# LPC176x5x register map
File version: 0.2
CPU: CM3 r0p0, little endian, no MPU, no FPU, 0x5 interrupt priority bits, 0x0 interrupts
Registers are 32-bit, read-write, no defined reset value unless marked. A register's access mark holds for its fields unless they carry their own. Offsets are from the block's base; [hi:lo] are bit positions; 'fields as' and 'values as' point back to an identical list.

## PINCONNECT — Pin connect block
Base 0x4002C000
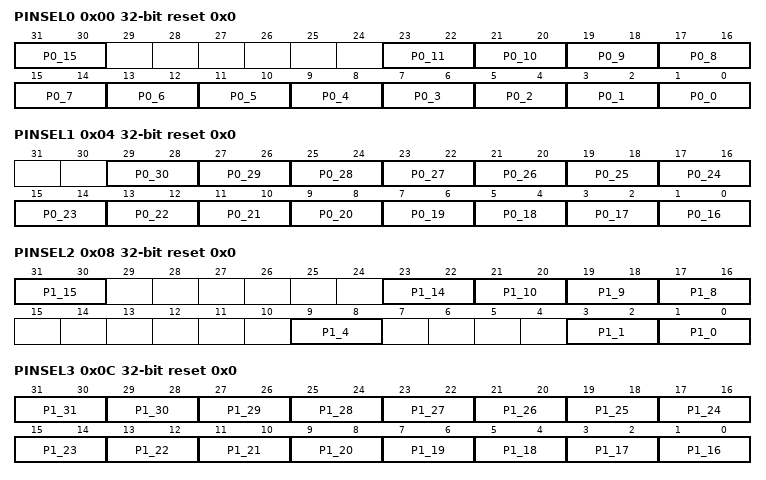
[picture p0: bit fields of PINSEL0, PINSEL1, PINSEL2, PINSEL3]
0x00 PINSEL0 reset 0x0 — Pin function select register 0.
  [31:30] P0_15 — Pin function select P0.15.
    0=GPIO_P0 (GPIO P0.15); 1=TXD1; 2=SCK0; 3=SCK
  [23:22] P0_11 — Pin function select P0.11.
    0=GPIO_P0 (GPIO P0.11); 1=RXD2; 2=SCL2; 3=MAT3 (MAT3.1)
  [21:20] P0_10 — Pin function select P0.10.
    0=GPIO_P0 (GPIO P0.10); 1=TXD2; 2=SDA2; 3=MAT3 (MAT3.0)
  [19:18] P0_9 — Pin function select P0.9.
    0=GPIO_P0 (GPIO P0.9); 1=I2STX_SDA; 2=MOSI1; 3=MAT2 (MAT2.3)
  [17:16] P0_8 — Pin function select P0.8.
    0=GPIO_P0 (GPIO P0.8.); 1=I2STX_WS; 2=MISO1; 3=MAT2 (MAT2.2)
  [15:14] P0_7 — Pin function select P0.7.
    0=GPIO_P0 (GPIO P0.7.); 1=I2STX_CLK; 2=SCK1; 3=MAT2 (MAT2.1)
  [13:12] P0_6 — Pin function select P0.6.
    0=GPIO_P0 (GPIO P0.6.); 1=I2SRX_SDA; 2=SSEL1; 3=MAT2 (MAT2.0)
  [11:10] P0_5 — Pin function select P0.5.
    0=GPIO_P0 (GPIO P0.5.); 1=I2SRX_WS; 2=TD2; 3=CAP2 (CAP2.1)
  [9:8] P0_4 — Pin function select P0.4.
    0=GPIO_P0 (GPIO P0.4.); 1=I2SRX_CLK; 2=RD2; 3=CAP2 (CAP2.0)
  [7:6] P0_3 — Pin function select P0.3.
    0=GPIO_P0 (GPIO P0.3.); 1=RXD0; 2=AD0 (AD0.6)
  [5:4] P0_2 — Pin function select P0.2.
    0=GPIO_P0 (GPIO P0.2); 1=TXD0; 2=AD0 (AD0.7)
  [3:2] P0_1 — Pin function select P0.1.
    0=GPIO_P0 (GPIO P0.1); 1=TD1; 2=RXD3; 3=SCL1
  [1:0] P0_0 — Pin function select P0.0.
    0=GPIO_P0 (GPIO P0.0); 1=RD1; 2=TXD3; 3=SDA1
0x04 PINSEL1 reset 0x0 — Pin function select register 1.
  [29:28] P0_30 — Pin function select P0.30.
    0=GPIO_P0 (GPIO P0.30); 1=USB_DM
  [27:26] P0_29 — Pin function select P0.29
    0=GPIO_P0 (GPIO P0.29); 1=USB_DP
  [25:24] P0_28 — Pin function select P0.28.
    0=GPIO_P0 (GPIO P0.28); 1=SCL0; 2=USB_SCL
  [23:22] P0_27 — Pin function select P0.27.
    0=GPIO_P0 (GPIO P0.27); 1=SDA0; 2=USB_SDA
  [21:20] P0_26 — Pin function select P0.26.
    0=GPIO_P0 (GPIO P0.26); 1=AD0 (AD0.3); 2=AOUT; 3=RXD3
  [19:18] P0_25 — Pin function select P0.25.
    0=GPIO_P0 (GPIO P0.25); 1=AD0 (AD0.2); 2=I2SRX_SDA; 3=TXD3
  [17:16] P0_24 — Pin function select P0.24.
    0=GPIO_P0 (GPIO P0.24.); 1=AD0 (AD0.1); 2=I2SRX_WS; 3=CAP3 (CAP3.1)
  [15:14] P0_23 — Pin function select P023.
    0=GPIO_P0 (GPIO P0.23.); 1=AD0 (AD0.0); 2=I2SRX_CLK; 3=CAP3 (CAP3.0)
  [13:12] P0_22 — Pin function select P022
    0=GPIO_P0 (GPIO P0.22.); 1=RTS1; 3=TD1
  [11:10] P0_21 — Pin function select P0.21.
    0=GPIO_PORT_0 (GPIO Port 0.21.); 1=RI1; 3=RD1
  [9:8] P0_20 — Pin function select P0.20.
    0=GPIO_P0 (GPIO P0.20.); 1=DTR1; 3=SCL1
  [7:6] P0_19 — Pin function select P019.
    0=GPIO_P0 (GPIO P0.19.); 1=DSR1; 3=SDA1
  [5:4] P0_18 — Pin function select P0.18.
    0=GPIO_P0 (GPIO P0.18); 1=DCD1; 2=MOSI0; 3=MOSI
  [3:2] P0_17 — Pin function select P0.17.
    0=GPIO_P0 (GPIO P0.17); 1=CTS1; 2=MISO0; 3=MISO
  [1:0] P0_16 — Pin function select P0.16.
    0=GPIO_P0 (GPIO P0.16); 1=RXD1; 2=SSEL0; 3=SSEL
0x08 PINSEL2 reset 0x0 — Pin function select register 2.
  [31:30] P1_15 — Pin function select P1.15.
    0=GPIO_P1 (GPIO P1.15); 1=ENET_REF_CLK
  [23:22] P1_14 — Pin function select P1.14.
    0=GPIO_P1 (GPIO P1.14); 1=ENET_RX_ER
  [21:20] P1_10 — Pin function select P1.10.
    0=GPIO_P1 (GPIO P1.10); 1=ENET_RXD1
  [19:18] P1_9 — Pin function select P1.9.
    0=GPIO_PORT_1 (GPIO Port 1.9); 1=ENET_RXD0
  [17:16] P1_8 — Pin function select P1.8.
    0=GPIO_P1 (GPIO P1.8.); 1=ENET_CRS
  [9:8] P1_4 — Pin function select P1.4.
    0=GPIO_P1 (GPIO P1.4.); 1=ENET_TX_EN
  [3:2] P1_1 — Pin function select P1.1.
    0=GPIO_P1 (GPIO P1.1); 1=ENET_TXD1
  [1:0] P1_0 — Pin function select P1.0.
    0=GPIO_P1 (GPIO P1.0); 1=ENET_TXD0
0x0C PINSEL3 reset 0x0 — Pin function select register 3.
  [31:30] P1_31 — Pin function select P1.31.
    0=GPIO_PORT_1 (GPIO Port 1.31); 2=SCK1; 3=AD0 (AD0.5)
  [29:28] P1_30 — Pin function select P1.30.
    0=GPIO_P1 (GPIO P1.30); 2=VBUS; 3=AD0 (AD0.4)
  [27:26] P1_29 — Pin function select P1.29
    0=GPIO_P1 (GPIO P1.29); 1=MCOB2; 2=PCAP1 (PCAP1.1); 3=MAT0 (MAT0.1)
  [25:24] P1_28 — Pin function select P1.28.
    0=GPIO_P1 (GPIO P1.28); 1=MCOA2; 2=PCAP1 (PCAP1.0); 3=MAT0 (MAT0.0)
  [23:22] P1_27 — Pin function select P1.27.
    0=GPIO_P1 (GPIO P1.27); 1=CLKOUT; 2=USB_OVRCR; 3=CAP0 (CAP0.1)
  [21:20] P1_26 — Pin function select P1.26.
    0=GPIO_P1 (GPIO P1.26); 1=MCOB1; 2=PWM1 (PWM1.6); 3=CAP0 (CAP0.0)
  [19:18] P1_25 — Pin function select P1.25.
    0=GPIO_P1 (GPIO P1.25); 1=MCOA1; 3=MAT1 (MAT1.1)
  [17:16] P1_24 — Pin function select P1.24.
    0=GPIO_P1 (GPIO P1.24.); 1=MCI2; 2=PWM1 (PWM1.5); 3=MOSI0
  [15:14] P1_23 — Pin function select P1.23.
    0=GPIO_P1 (GPIO P1.23.); 1=MCI1; 2=PWM1 (PWM1.4); 3=MISO0
  [13:12] P1_22 — Pin function select P1.22
    0=GPIO_P1 (GPIO P1.22.); 1=MCOB0; 2=USB_PWRD; 3=MAT1 (MAT1.0)
  [11:10] P1_21 — Pin function select P1.21.
    0=GPIO_P1 (GPIO P1.21.); 1=MCABORT; 2=PWM1 (PWM1.3); 3=SSEL0
  [9:8] P1_20 — Pin function select P1.20.
    0=GPIO_P1 (GPIO P1.20.); 1=MCI0; 2=PWM1 (PWM1.2); 3=SCK0
  [7:6] P1_19 — Pin function select P1.19.
    0=GPIO_P1 (GPIO P1.19.); 1=MCOA0; 2=USB_PPWR; 3=CAP1 (CAP1.1)
  [5:4] P1_18 — Pin function select P1.18.
    0=GPIO_P1 (GPIO P1.18); 1=USB_UP_LED; 2=PWM1 (PWM1.1); 3=CAP1 (CAP1.0)
  [3:2] P1_17 — Pin function select P1.17.
    0=GPIO_P1 (GPIO P1.17); 1=ENET_MDIO
  [1:0] P1_16 — Pin function select P1.16.
    0=GPIO_P1 (GPIO P1.16); 1=ENET_MDC
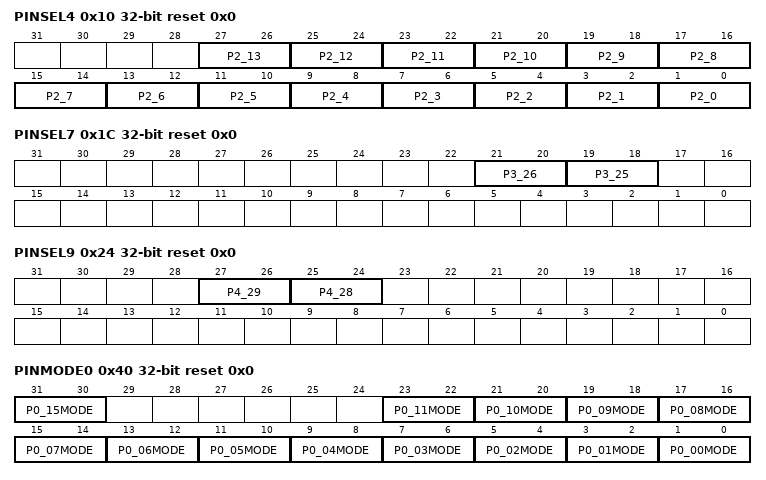
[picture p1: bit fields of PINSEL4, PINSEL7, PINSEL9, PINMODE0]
0x10 PINSEL4 reset 0x0 — Pin function select register 4
  [27:26] P2_13 — Pin function select P2.13.
    0=GPIO_P2 (GPIO P2.13); 1=EINT3; 3=I2STX_SDA
  [25:24] P2_12 — Pin function select P2.12.
    0=GPIO_P2 (GPIO P2.12); 1=EINT2; 3=I2STX_WS
  [23:22] P2_11 — Pin function select P2.11.
    0=GPIO_P2 (GPIO P2.11); 1=EINT1; 3=I2STX_CLK
  [21:20] P2_10 — Pin function select P2.10.
    0=GPIO_P2 (GPIO P2.10); 1=EINT0; 2=NMI
  [19:18] P2_9 — Pin function select P2.9.
    0=GPIO_P2 (GPIO P2.9); 1=USB_CONNECT; 2=RXD2; 3=ENET_MDIO
  [17:16] P2_8 — Pin function select P2.8.
    0=GPIO_P2 (GPIO P2.8.); 1=TD2; 2=TXD2; 3=ENET_MDC
  [15:14] P2_7 — Pin function select P2.7.
    0=GPIO_P2 (GPIO P2.7.); 1=RD2; 2=RTS1
  [13:12] P2_6 — Pin function select P2.6.
    0=GPIO_P2 (GPIO P2.6.); 1=PCAP1 (PCAP1.0); 2=RI1
  [11:10] P2_5 — Pin function select P2.5.
    0=GPIO_P2 (GPIO P2.5.); 1=PWM1 (PWM1.6); 2=DTR1
  [9:8] P2_4 — Pin function select P2.4.
    0=GPIO_P2 (GPIO P2.4.); 1=PWM1 (PWM1.5); 2=DSR1
  [7:6] P2_3 — Pin function select P2.3.
    0=GPIO_P2 (GPIO P2.3.); 1=PWM1 (PWM1.4); 2=DCD1
  [5:4] P2_2 — Pin function select P2.2.
    0=GPIO_P2 (GPIO P2.2); 1=PWM1 (PWM1.3); 2=CTS1
  [3:2] P2_1 — Pin function select P2.1.
    0=GPIO_P2 (GPIO P2.1); 1=PWM1 (PWM1.2); 2=RXD1
  [1:0] P2_0 — Pin function select P2.0.
    0=GPIO_P2 (GPIO P2.0); 1=PWM1 (PWM1.1); 2=TXD1
0x1C PINSEL7 reset 0x0 — Pin function select register 7
  [21:20] P3_26 — Pin function select P3.26.
    0=GPIO_P3 (GPIO P3.26); 1=STCLK; 2=MAT0 (MAT0.1); 3=PWM1 (PWM1.3)
  [19:18] P3_25 — Pin function select P3.25.
    0=GPIO_P3 (GPIO P3.25); 2=MAT0 (MAT0.0); 3=PWM1 (PWM1.2)
0x24 PINSEL9 reset 0x0 — Pin function select register 9
  [27:26] P4_29 — Pin function select P4.29.
    0=GPIO_P4 (GPIO P4.29); 1=TX_MCLK; 2=MAT2 (MAT2.1); 3=RXD3
  [25:24] P4_28 — Pin function select P4.28.
    0=GPIO_P4 (GPIO P4.28); 1=RX_MCLK; 2=MAT2 (MAT2.0); 3=TXD3
0x28 PINSEL10 reset 0x0 — Pin function select register 10
  [3] TPIUCTRL — TPIU interface pins control.
    0=DISABLED (Disabled. TPIU interface is disabled.); 1=ENABLED (Enabled. TPIU interface is enabled. TPIU signals are available on the pins hosting them regardless of the PINSEL4 content.)
0x40 PINMODE0 reset 0x0 — Pin mode select register 0
  [31:30] P0_15MODE — Port 0 pin 15 control.
    0=PULL_UP (Pull-up. P0.15 pin has a pull-up resistor enabled.); 1=REPEATER (Repeater. P0.15 pin has repeater mode enabled.); 2=DISABLED (Disabled. P0.15 pin has neither pull-up nor pull-down.); 3=PULL_DOWN (Pull-down. P0.15 has a pull-down resistor enabled.)
  [23:22] P0_11MODE — Port 0 pin 11 control.
    0=PULL_UP (Pull-up. P0.11 pin has a pull-up resistor enabled.); 1=REPEATER (Repeater. P0.11 pin has repeater mode enabled.); 2=DISABLED (Disabled. P0.11 pin has neither pull-up nor pull-down.); 3=PULL_DOWN (Pull-down. P0.11 has a pull-down resistor enabled.)
  [21:20] P0_10MODE — Port 0 pin 10 control.
    0=PULL_UP (Pull-up. P0.10 pin has a pull-up resistor enabled.); 1=REPEATER (Repeater. P0.10 pin has repeater mode enabled.); 2=DISABLED (Disabled. P0.10 pin has neither pull-up nor pull-down.); 3=PULL_DOWN (Pull-down. P0.10 has a pull-down resistor enabled.)
  [19:18] P0_09MODE — Port 0 pin 9 control.
    0=PULL_UP (Pull-up. P0.9 pin has a pull-up resistor enabled.); 1=REPEATER (Repeater. P0.9 pin has repeater mode enabled.); 2=DISABLED (Disabled. P0.9 pin has neither pull-up nor pull-down.); 3=PULL_DOWN (Pull-down. P0.9 has a pull-down resistor enabled.)
  [17:16] P0_08MODE — Port 0 pin 8 control.
    0=PULL_UP (Pull-up. P0.8 pin has a pull-up resistor enabled.); 1=REPEATER (Repeater. P0.8 pin has repeater mode enabled.); 2=DISABLED (Disabled. P0.8 pin has neither pull-up nor pull-down.); 3=PULL_DOWN (Pull-down. P0.8 has a pull-down resistor enabled.)
  [15:14] P0_07MODE — Port 0 pin 7 control.
    0=PULL_UP (Pull-up. P0.7 pin has a pull-up resistor enabled.); 1=REPEATER (Repeater. P0.7 pin has repeater mode enabled.); 2=DISABLED (Disabled. P0.7 pin has neither pull-up nor pull-down.); 3=PULL_DOWN (Pull-down. P0.7 has a pull-down resistor enabled.)
  [13:12] P0_06MODE — Port 0 pin 6 control.
    0=PULL_UP (Pull-up. P0.6 pin has a pull-up resistor enabled.); 1=DISABLED (Disabled. Repeater. P0.6 pin has repeater mode enabled.); 2=DISABLED (Disabled. P0.6 pin has neither pull-up nor pull-down.); 3=PULL_DOWN (Pull-down. P0.6 has a pull-down resistor enabled.)
  [11:10] P0_05MODE — Port 0 pin 5 control.
    0=PULL_UP (Pull-up. P0.5 pin has a pull-up resistor enabled.); 1=REPEATER (Repeater. P0.5 pin has repeater mode enabled.); 2=DISABLED (Disabled. P0.5 pin has neither pull-up nor pull-down.); 3=PULL_DOWN (Pull-down. P0.5 has a pull-down resistor enabled.)
  [9:8] P0_04MODE — Port 0 pin 4 control.
    0=PULL_UP (Pull-up. P0.4 pin has a pull-up resistor enabled.); 1=REPEATER (Repeater. P0.4 pin has repeater mode enabled.); 2=DISABLED (Disabled. P0.4 pin has neither pull-up nor pull-down.); 3=PULL_DOWN (Pull-down. P0.4 has a pull-down resistor enabled.)
  [7:6] P0_03MODE — Port 0 pin 3 control.
    0=PULL_UP (Pull-up. P0.3 pin has a pull-up resistor enabled.); 1=REPEATER (Repeater. P0.3 pin has repeater mode enabled.); 2=DISABLED (Disabled. P0.3 pin has neither pull-up nor pull-down.); 3=PULL_DOWN (Pull-down. P0.3 has a pull-down resistor enabled.)
  [5:4] P0_02MODE — Port 0 pin 2 control.
    0=PULL_UP (Pull-up. P0.2 pin has a pull-up resistor enabled.); 1=REPEATER (Repeater. P0.2 pin has repeater mode enabled.); 2=DISABLED (Disabled. P0.2 pin has neither pull-up nor pull-down.); 3=PULL_DOWN (Pull-down. P0.2 has a pull-down resistor enabled.)
  [3:2] P0_01MODE — Port 0 pin 1 control.
    0=PULL_UP (Pull-up. P0.1 pin has a pull-up resistor enabled.); 1=REPEATER (Repeater. P0.1 pin has repeater mode enabled.); 2=DISABLED (Disabled. P0.1 pin has neither pull-up nor pull-down.); 3=PULL_DOWN (Pull-down. P0.1 has a pull-down resistor enabled.)
  [1:0] P0_00MODE — Port 0 pin 0 on-chip pull-up/down resistor control.
    0=PULL_UP (Pull-up. P0.0 pin has a pull-up resistor enabled.); 1=REPEATER (Repeater. P0.0 pin has repeater mode enabled.); 2=DISABLED (Disabled. P0.0 pin has neither pull-up nor pull-down.); 3=PULL_DOWN (Pull-down. P0.0 has a pull-down resistor enabled.)
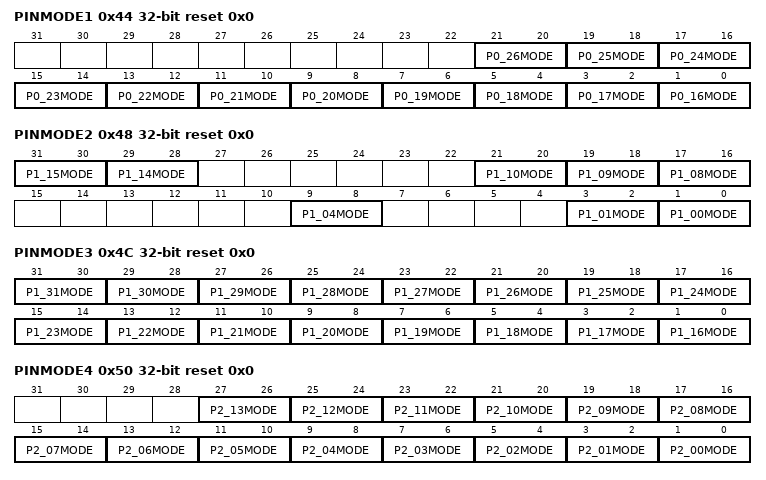
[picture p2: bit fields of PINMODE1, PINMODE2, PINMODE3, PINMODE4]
0x44 PINMODE1 reset 0x0 — Pin mode select register 1
  [21:20] P0_26MODE — Port 1 pin 26 control.
    0=PULL_UP (Pull-up. P0.26 pin has a pull-up resistor enabled.); 1=REPEATER (Repeater. P0.26 pin has repeater mode enabled.); 2=DISABLED (Disabled. P0.26 pin has neither pull-up nor pull-down.); 3=PULL_DOWN (Pull-down. P0.26 has a pull-down resistor enabled.)
  [19:18] P0_25MODE — Port 1 pin 25 control.
    0=PULL_UP (Pull-up. P0.25 pin has a pull-up resistor enabled.); 1=REPEATER (Repeater. P0.25 pin has repeater mode enabled.); 2=DISABLED (Disabled. P0.25 pin has neither pull-up nor pull-down.); 3=PULL_DOWN (Pull-down. P0.25 has a pull-down resistor enabled.)
  [17:16] P0_24MODE — Port 1 pin 24 control.
    0=PULL_UP (Pull-up. P0.24 pin has a pull-up resistor enabled.); 1=REPEATER (Repeater. P0.24 pin has repeater mode enabled.); 2=DISABLED (Disabled. P0.24 pin has neither pull-up nor pull-down.); 3=PULL_DOWN (Pull-down. P0.24 has a pull-down resistor enabled.)
  [15:14] P0_23MODE — Port 1 pin 23 control.
    0=PULL_UP (Pull-up. P0.23 pin has a pull-up resistor enabled.); 1=REPEATER (Repeater. P0.23 pin has repeater mode enabled.); 2=DISABLED (Disabled. P0.23 pin has neither pull-up nor pull-down.); 3=PULL_DOWN (Pull-down. P0.23 has a pull-down resistor enabled.)
  [13:12] P0_22MODE — Port 1 pin 22 control.
    0=PULL_UP (Pull-up. P0.22 pin has a pull-up resistor enabled.); 1=REPEATER (Repeater. P0.22 pin has repeater mode enabled.); 2=DISABLED (Disabled. P0.22 pin has neither pull-up nor pull-down.); 3=PULL_DOWN (Pull-down. P0.22 has a pull-down resistor enabled.)
  [11:10] P0_21MODE — Port 1 pin 21 control.
    0=PULL_UP (Pull-up. P0.21 pin has a pull-up resistor enabled.); 1=REPEATER (Repeater. P0.21 pin has repeater mode enabled.); 2=DISABLED (Disabled. P0.21 pin has neither pull-up nor pull-down.); 3=PULL_DOWN (Pull-down. P0.21 has a pull-down resistor enabled.)
  [9:8] P0_20MODE — Port 1 pin 20 control.
    0=PULL_UP (Pull-up. P0.20 pin has a pull-up resistor enabled.); 1=REPEATER (Repeater. P0.20 pin has repeater mode enabled.); 2=DISABLED (Disabled. P0.20 pin has neither pull-up nor pull-down.); 3=PULL_DOWN (Pull-down. P0.20 has a pull-down resistor enabled.)
  [7:6] P0_19MODE — Port 1 pin 19 control.
    0=PULL_UP (Pull-up. P0.19 pin has a pull-up resistor enabled.); 1=REPEATER (Repeater. P0.19 pin has repeater mode enabled.); 2=DISABLED (Disabled. P0.19 pin has neither pull-up nor pull-down.); 3=PULL_DOWN (Pull-down. P0.19 has a pull-down resistor enabled.)
  [5:4] P0_18MODE — Port 1 pin 18 control.
    0=PULL_UP (Pull-up. P0.18 pin has a pull-up resistor enabled.); 1=REPEATER (Repeater. P0.18 pin has repeater mode enabled.); 2=DISABLED (Disabled. P0.18 pin has neither pull-up nor pull-down.); 3=PULL_DOWN (Pull-down. P0.18 has a pull-down resistor enabled.)
  [3:2] P0_17MODE — Port 1 pin 17 control.
    0=PULL_UP (Pull-up. P0.17 pin has a pull-up resistor enabled.); 1=REPEATER (Repeater. P0.17 pin has repeater mode enabled.); 2=DISABLED (Disabled. P0.17 pin has neither pull-up nor pull-down.); 3=PULL_DOWN (Pull-down. P0.17 has a pull-down resistor enabled.)
  [1:0] P0_16MODE — Port 1 pin 16 control.
    0=PULL_UP (Pull-up. P0.16 pin has a pull-up resistor enabled.); 1=REPEATER (Repeater. P0.16 pin has repeater mode enabled.); 2=DISABLED (Disabled. P0.16 pin has neither pull-up nor pull-down.); 3=PULL_DOWN (Pull-down. P0.16 has a pull-down resistor enabled.)
0x48 PINMODE2 reset 0x0 — Pin mode select register 2
  [31:30] P1_15MODE — Port 1 pin 15 control.
    0=PULL_UP (Pull-up. P1.15 pin has a pull-up resistor enabled.); 1=REPEATER (Repeater. P1.15 pin has repeater mode enabled.); 2=DISABLED (Disabled. P1.15 pin has neither pull-up nor pull-down.); 3=PULL_DOWN (Pull-down. P1.15 has a pull-down resistor enabled.)
  [29:28] P1_14MODE — Port 1 pin 14 control.
    0=PULL_UP (Pull-up. P1.14 pin has a pull-up resistor enabled.); 1=REPEATER (Repeater. P1.14 pin has repeater mode enabled.); 2=DISABLED (Disabled. P1.14 pin has neither pull-up nor pull-down.); 3=PULL_DOWN (Pull-down. P1.14 has a pull-down resistor enabled.)
  [21:20] P1_10MODE — Port 1 pin 10 control.
    0=PULL_UP (Pull-up. P1.10 pin has a pull-up resistor enabled.); 1=REPEATER (Repeater. P1.10 pin has repeater mode enabled.); 2=DISABLED (Disabled. P1.10 pin has neither pull-up nor pull-down.); 3=PULL_DOWN (Pull-down. P1.10 has a pull-down resistor enabled.)
  [19:18] P1_09MODE — Port 1 pin 9 control.
    0=PULL_UP (Pull-up. P1.9 pin has a pull-up resistor enabled.); 1=REPEATER (Repeater. P1.9 pin has repeater mode enabled.); 2=DISABLED (Disabled. P1.9 pin has neither pull-up nor pull-down.); 3=PULL_DOWN (Pull-down. P1.9 has a pull-down resistor enabled.)
  [17:16] P1_08MODE — Port 1 pin 8 control.
    0=PULL_UP (Pull-up. P1.8 pin has a pull-up resistor enabled.); 1=REPEATER (Repeater. P1.8 pin has repeater mode enabled.); 2=DISABLED (Disabled. P1.8 pin has neither pull-up nor pull-down.); 3=PULL_DOWN (Pull-down. P1.8 has a pull-down resistor enabled.)
  [9:8] P1_04MODE — Port 1 pin 4 control.
    0=PULL_UP (Pull-up. P1.4 pin has a pull-up resistor enabled.); 1=REPEATER (Repeater. P1.4 pin has repeater mode enabled.); 2=DISABLED (Disabled. P1.4 pin has neither pull-up nor pull-down.); 3=PULL_DOWN (Pull-down. P1.4 has a pull-down resistor enabled.)
  [3:2] P1_01MODE — Port 1 pin 1 control.
    0=PULL_UP (Pull-up. P1.1 pin has a pull-up resistor enabled.); 1=REPEATER (Repeater. P1.1 pin has repeater mode enabled.); 2=DISABLED (Disabled. P1.1 pin has neither pull-up nor pull-down.); 3=PULL_DOWN (Pull-down. P1.1 has a pull-down resistor enabled.)
  [1:0] P1_00MODE — Port 1 pin 0 control.
    0=PULL_UP (Pull-up. P1.0 pin has a pull-up resistor enabled.); 1=REPEATER (Repeater. P1.0 pin has repeater mode enabled.); 2=DISABLED (Disabled. P1.0 pin has neither pull-up nor pull-down.); 3=PULL_DOWN (Pull-down. P1.0 has a pull-down resistor enabled.)
0x4C PINMODE3 reset 0x0 — Pin mode select register 3.
  [31:30] P1_31MODE — Port 1 pin 31 control.
    0=PULL_UP (Pull-up. P1.31 pin has a pull-up resistor enabled.); 1=REPEATER (Repeater. P1.31 pin has repeater mode enabled.); 2=DISABLED (Disabled. P1.31 pin has neither pull-up nor pull-down.); 3=PULL_DOWN (Pull-down. P1.31 has a pull-down resistor enabled.)
  [29:28] P1_30MODE — Port 1 pin 30 control.
    0=PULL_UP (Pull-up. P1.30 pin has a pull-up resistor enabled.); 1=REPEATER (Repeater. P1.30 pin has repeater mode enabled.); 2=DISABLED (Disabled. P1.30 pin has neither pull-up nor pull-down.); 3=PULL_DOWN (Pull-down. P1.30 has a pull-down resistor enabled.)
  [27:26] P1_29MODE — Port 1 pin 29 control.
    0=PULL_UP (Pull-up. P1.29 pin has a pull-up resistor enabled.); 1=REPEATER (Repeater. P1.29 pin has repeater mode enabled.); 2=DISABLED (Disabled. P1.29 pin has neither pull-up nor pull-down.); 3=PULL_DOWN (Pull-down. P1.29 has a pull-down resistor enabled.)
  [25:24] P1_28MODE — Port 1 pin 28 control.
    0=PULL_UP (Pull-up. P1.28 pin has a pull-up resistor enabled.); 1=REPEATER (Repeater. P1.28 pin has repeater mode enabled.); 2=DISABLED (Disabled. P1.28 pin has neither pull-up nor pull-down.); 3=PULL_DOWN (Pull-down. P1.28 has a pull-down resistor enabled.)
  [23:22] P1_27MODE — Port 1 pin 27 control.
    0=PULL_UP (Pull-up. P1.27 pin has a pull-up resistor enabled.); 1=REPEATER (Repeater. P1.27 pin has repeater mode enabled.); 2=DISABLED (Disabled. P1.27 pin has neither pull-up nor pull-down.); 3=PULL_DOWN (Pull-down. P1.27 has a pull-down resistor enabled.)
  [21:20] P1_26MODE — Port 1 pin 26 control.
    0=PULL_UP (Pull-up. P1.26 pin has a pull-up resistor enabled.); 1=REPEATER (Repeater. P1.26 pin has repeater mode enabled.); 2=DISABLED (Disabled. P1.26 pin has neither pull-up nor pull-down.); 3=PULL_DOWN (Pull-down. P1.26 has a pull-down resistor enabled.)
  [19:18] P1_25MODE — Port 1 pin 25 control.
    0=PULL_UP (Pull-up. P1.25 pin has a pull-up resistor enabled.); 1=REPEATER (Repeater. P1.25 pin has repeater mode enabled.); 2=DISABLED (Disabled. P1.25 pin has neither pull-up nor pull-down.); 3=PULL_DOWN (Pull-down. P1.25 has a pull-down resistor enabled.)
  [17:16] P1_24MODE — Port 1 pin 24 control.
    0=PULL_UP (Pull-up. P1.24 pin has a pull-up resistor enabled.); 1=REPEATER (Repeater. P1.24 pin has repeater mode enabled.); 2=DISABLED (Disabled. P1.24 pin has neither pull-up nor pull-down.); 3=PULL_DOWN (Pull-down. P1.24 has a pull-down resistor enabled.)
  [15:14] P1_23MODE — Port 1 pin 23 control.
    0=PULL_UP (Pull-up. P1.23 pin has a pull-up resistor enabled.); 1=REPEATER (Repeater. P1.23 pin has repeater mode enabled.); 2=DISABLED (Disabled. P1.23 pin has neither pull-up nor pull-down.); 3=PULL_DOWN (Pull-down. P1.23 has a pull-down resistor enabled.)
  [13:12] P1_22MODE — Port 1 pin 22 control.
    0=PULL_UP (Pull-up. P1.22 pin has a pull-up resistor enabled.); 1=REPEATER (Repeater. P1.22 pin has repeater mode enabled.); 2=DISABLED (Disabled. P1.22 pin has neither pull-up nor pull-down.); 3=PULL_DOWN (Pull-down. P1.22 has a pull-down resistor enabled.)
  [11:10] P1_21MODE — Port 1 pin 21 control.
    0=PULL_UP (Pull-up. P1.21 pin has a pull-up resistor enabled.); 1=REPEATER (Repeater. P1.21 pin has repeater mode enabled.); 2=DISABLED (Disabled. P1.21 pin has neither pull-up nor pull-down.); 3=PULL_DOWN (Pull-down. P1.21 has a pull-down resistor enabled.)
  [9:8] P1_20MODE — Port 1 pin 20 control.
    0=PULL_UP (Pull-up. P1.20 pin has a pull-up resistor enabled.); 1=REPEATER (Repeater. P1.20 pin has repeater mode enabled.); 2=DISABLED (Disabled. P1.20 pin has neither pull-up nor pull-down.); 3=PULL_DOWN (Pull-down. P1.20 has a pull-down resistor enabled.)
  [7:6] P1_19MODE — Port 1 pin 19 control.
    0=PULL_UP (Pull-up. P1.19 pin has a pull-up resistor enabled.); 1=REPEATER (Repeater. P1.19 pin has repeater mode enabled.); 2=DISABLED (Disabled. P1.19 pin has neither pull-up nor pull-down.); 3=PULL_DOWN (Pull-down. P1.19 has a pull-down resistor enabled.)
  [5:4] P1_18MODE — Port 1 pin 18 control.
    0=PULL_UP (Pull-up. P1.18 pin has a pull-up resistor enabled.); 1=REPEATER (Repeater. P1.18 pin has repeater mode enabled.); 2=DISABLED (Disabled. P1.18 pin has neither pull-up nor pull-down.); 3=PULL_DOWN (Pull-down. P1.18 has a pull-down resistor enabled.)
  [3:2] P1_17MODE — Port 1 pin 17 control.
    0=PULL_UP (Pull-up. P1.17 pin has a pull-up resistor enabled.); 1=REPEATER (Repeater. P1.17 pin has repeater mode enabled.); 2=DISABLED (Disabled. P1.17 pin has neither pull-up nor pull-down.); 3=PULL_DOWN (Pull-down. P1.17 has a pull-down resistor enabled.)
  [1:0] P1_16MODE — Port 1 pin 16 control.
    0=PULL_UP (Pull-up. P1.16 pin has a pull-up resistor enabled.); 1=REPEATER (Repeater. P1.16 pin has repeater mode enabled.); 2=DISABLED (Disabled. P1.16 pin has neither pull-up nor pull-down.); 3=PULL_DOWN (Pull-down. P1.16 has a pull-down resistor enabled.)
0x50 PINMODE4 reset 0x0 — Pin mode select register 4
  [27:26] P2_13MODE — Port 2 pin 13 control.
    0=PULL_UP (Pull-up. P2.13 pin has a pull-up resistor enabled.); 1=REPEATER (Repeater. P2.13 pin has repeater mode enabled.); 2=DISABLED (Disabled. P2.13 pin has neither pull-up nor pull-down.); 3=PULL_DOWN (Pull-down. P2.13 has a pull-down resistor enabled.)
  [25:24] P2_12MODE — Port 2 pin 12 control.
    0=PULL_UP (Pull-up. P2.12 pin has a pull-up resistor enabled.); 1=REPEATER (Repeater. P2.12 pin has repeater mode enabled.); 2=DISABLED (Disabled. P2.12 pin has neither pull-up nor pull-down.); 3=PULL_DOWN (Pull-down. P2.12 has a pull-down resistor enabled.)
  [23:22] P2_11MODE — Port 2 pin 11 control.
    0=PULL_UP (Pull-up. P2.11 pin has a pull-up resistor enabled.); 1=REPEATER (Repeater. P2.11 pin has repeater mode enabled.); 2=DISABLED (Disabled. P2.11 pin has neither pull-up nor pull-down.); 3=PULL_DOWN (Pull-down. P2.11 has a pull-down resistor enabled.)
  [21:20] P2_10MODE — Port 2 pin 10 control.
    0=PULL_UP (Pull-up. P2.10 pin has a pull-up resistor enabled.); 1=REPEATER (Repeater. P2.10 pin has repeater mode enabled.); 2=DISABLED (Disabled. P2.10 pin has neither pull-up nor pull-down.); 3=PULL_DOWN (Pull-down. P2.10 has a pull-down resistor enabled.)
  [19:18] P2_09MODE — Port 2 pin 9 control.
    0=PULL_UP (Pull-up. P2.9 pin has a pull-up resistor enabled.); 1=REPEATER (Repeater. P2.9 pin has repeater mode enabled.); 2=DISABLED (Disabled. P2.9 pin has neither pull-up nor pull-down.); 3=PULL_DOWN (Pull-down. P2.9 has a pull-down resistor enabled.)
  [17:16] P2_08MODE — Port 2 pin 8 control.
    0=PULL_UP (Pull-up. P2.8 pin has a pull-up resistor enabled.); 1=REPEATER (Repeater. P2.8 pin has repeater mode enabled.); 2=DISABLED (Disabled. P2.8 pin has neither pull-up nor pull-down.); 3=PULL_DOWN (Pull-down. P2.8 has a pull-down resistor enabled.)
  [15:14] P2_07MODE — Port 2 pin 7 control.
    0=PULL_UP (Pull-up. P2.7 pin has a pull-up resistor enabled.); 1=REPEATER (Repeater. P2.7 pin has repeater mode enabled.); 2=DISABLED (Disabled. P2.7 pin has neither pull-up nor pull-down.); 3=PULL_DOWN (Pull-down. P2.7 has a pull-down resistor enabled.)
  [13:12] P2_06MODE — Port 2 pin 6 control.
    0=PULL_UP (Pull-up. P2.6 pin has a pull-up resistor enabled.); 1=REPEATER (Repeater. P2.6 pin has repeater mode enabled.); 2=DISABLED (Disabled. P2.6 pin has neither pull-up nor pull-down.); 3=PULL_DOWN (Pull-down. P2.6 has a pull-down resistor enabled.)
  [11:10] P2_05MODE — Port 2 pin 5 control.
    0=PULL_UP (Pull-up. P2.5 pin has a pull-up resistor enabled.); 1=REPEATER (Repeater. P2.5 pin has repeater mode enabled.); 2=DISABLED (Disabled. P2.5 pin has neither pull-up nor pull-down.); 3=PULL_DOWN (Pull-down. P2.5 has a pull-down resistor enabled.)
  [9:8] P2_04MODE — Port 2 pin 4 control.
    0=PULL_UP (Pull-up. P2.4 pin has a pull-up resistor enabled.); 1=REPEATER (Repeater. P2.4 pin has repeater mode enabled.); 2=DISABLED (Disabled. P2.4 pin has neither pull-up nor pull-down.); 3=PULL_DOWN (Pull-down. P2.4 has a pull-down resistor enabled.)
  [7:6] P2_03MODE — Port 2 pin 3 control.
    0=PULL_UP (Pull-up. P2.3 pin has a pull-up resistor enabled.); 1=REPEATER (Repeater. P2.3 pin has repeater mode enabled.); 2=DISABLED (Disabled. P2.3 pin has neither pull-up nor pull-down.); 3=PULL_DOWN (Pull-down. P2.3 has a pull-down resistor enabled.)
  [5:4] P2_02MODE — Port 2 pin 2 control.
    0=PULL_UP (Pull-up. P2.2 pin has a pull-up resistor enabled.); 1=REPEATER (Repeater. P2.2 pin has repeater mode enabled.); 2=DISABLED (Disabled. P2.2 pin has neither pull-up nor pull-down.); 3=PULL_DOWN (Pull-down. P2.2 has a pull-down resistor enabled.)
  [3:2] P2_01MODE — Port 2 pin 1 control.
    0=PULL_UP (Pull-up. P2.1 pin has a pull-up resistor enabled.); 1=REPEATER (Repeater. P2.1 pin has repeater mode enabled.); 2=DISABLED (Disabled. P2.1 pin has neither pull-up nor pull-down.); 3=PULL_DOWN (Pull-down. P2.1 has a pull-down resistor enabled.)
  [1:0] P2_00MODE — Port 2 pin 0 control.
    0=PULL_UP (Pull-up. P2.0 pin has a pull-up resistor enabled.); 1=REPEATER (Repeater. P2.0 pin has repeater mode enabled.); 2=DISABLED (Disabled. P2.0 pin has neither pull-up nor pull-down.); 3=PULL_DOWN (Pull-down. P2.0 has a pull-down resistor enabled.)
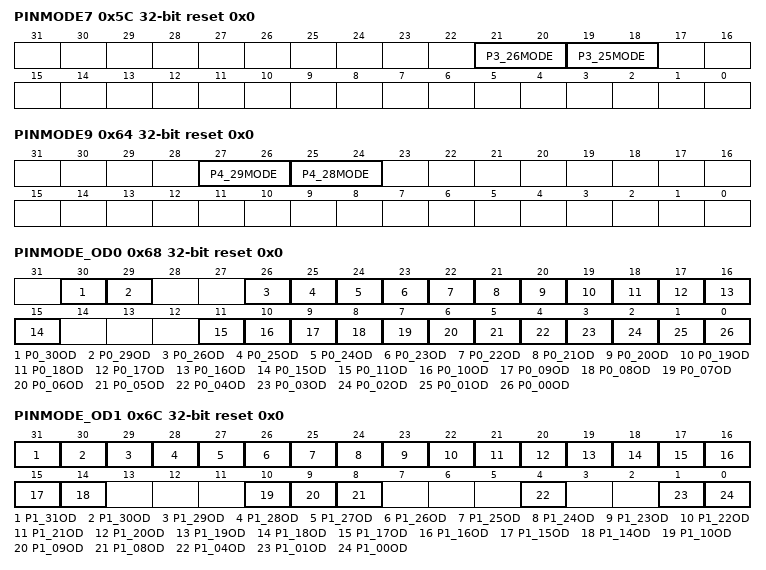
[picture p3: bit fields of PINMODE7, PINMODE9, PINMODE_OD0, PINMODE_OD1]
0x5C PINMODE7 reset 0x0 — Pin mode select register 7
  [21:20] P3_26MODE — Port 3 pin 26 control.
    0=PULL_UP (Pull-up. P3.26 pin has a pull-up resistor enabled.); 1=REPEATER (Repeater. P3.26 pin has repeater mode enabled.); 2=DISABLED (Disabled. P3.26 pin has neither pull-up nor pull-down.); 3=PULL_DOWN (Pull-down. P3.26 has a pull-down resistor enabled.)
  [19:18] P3_25MODE — Port 3 pin 25 control.
    0=PULL_UP (Pull-up. P3.25 pin has a pull-up resistor enabled.); 1=REPEATER (Repeater. P3.25 pin has repeater mode enabled.); 2=DISABLED (Disabled. P3.25 pin has neither pull-up nor pull-down.); 3=PULL_DOWN (Pull-down. P3.25 has a pull-down resistor enabled.)
0x64 PINMODE9 reset 0x0 — Pin mode select register 9
  [27:26] P4_29MODE — Port 4 pin 29 control.
    0=PULL_UP (Pull-up. P4.29 pin has a pull-up resistor enabled.); 1=REPEATER (Repeater. P4.29 pin has repeater mode enabled.); 2=DISABLED (Disabled. P4.29 pin has neither pull-up nor pull-down.); 3=PULL_DOWN (Pull-down. P4.29 has a pull-down resistor enabled.)
  [25:24] P4_28MODE — Port 4 pin 28 control.
    0=PULL_UP (Pull-up. P4.28 pin has a pull-up resistor enabled.); 1=REPEATER (Repeater. P4.28 pin has repeater mode enabled.); 2=DISABLED (Disabled. P4.28 pin has neither pull-up nor pull-down.); 3=PULL_DOWN (Pull-down. P4.28 has a pull-down resistor enabled.)
0x68 PINMODE_OD0 reset 0x0 — Open drain mode control register 0
  [30] P0_30OD — Port 0 pin 30 open drain mode control
    0=NORMAL (Normal. P0.30 pin is in the normal (not open drain) mode.); 1=OPEN_DRAIN (Open-drain. P0.30 pin is in the open drain mode.)
  [29] P0_29OD — Port 0 pin 29 open drain mode control
    0=NORMAL (Normal. P0.29 pin is in the normal (not open drain) mode.); 1=OPEN_DRAIN (Open-drain. P0.29 pin is in the open drain mode.)
  [26] P0_26OD — Port 0 pin 26 open drain mode control
    0=NORMAL (Normal. P0.26 pin is in the normal (not open drain) mode.); 1=OPEN_DRAIN (Open-drain. P0.26 pin is in the open drain mode.)
  [25] P0_25OD — Port 0 pin 25 open drain mode control
    0=NORMAL (Normal. P0.25 pin is in the normal (not open drain) mode.); 1=OPEN_DRAIN (Open-drain. P0.25 pin is in the open drain mode.)
  [24] P0_24OD — Port 0 pin 24open drain mode control
    0=NORMAL (Normal. P0.23 pin is in the normal (not open drain) mode.); 1=OPEN_DRAIN (Open-drain. P0.23 pin is in the open drain mode.)
  [23] P0_23OD — Port 0 pin 23 open drain mode control
    values as P0_24OD
  [22] P0_22OD — Port 0 pin 22 open drain mode control
    0=NORMAL (Normal. P0.22 pin is in the normal (not open drain) mode.); 1=OPEN_DRAIN (Open-drain. P0.22 pin is in the open drain mode.)
  [21] P0_21OD — Port 0 pin 21 open drain mode control
    0=NORMAL (Normal. P0.21 pin is in the normal (not open drain) mode.); 1=OPEN_DRAIN (Open-drain. P0.21 pin is in the open drain mode.)
  [20] P0_20OD — Port 0 pin 20open drain mode control. Pins may potentially be used for I2C-buses using standard port pins. If so, they should be configured for open drain mode via the related bits in PINMODE_OD0.
    0=NORMAL (Normal. P0.20 pin is in the normal (not open drain) mode.); 1=OPEN_DRAIN (Open-drain. P0.20 pin is in the open drain mode.)
  [19] P0_19OD — Port 0 pin 19 open drain mode control. Pins may potentially be used for I2C-buses using standard port pins. If so, they should be configured for open drain mode via the related bits in PINMODE_OD0.
    0=NORMAL (Normal. P0.19 pin is in the normal (not open drain) mode.); 1=OPEN_DRAIN (Open-drain. P0.19 pin is in the open drain mode.)
  [18] P0_18OD — Port 0 pin 18 open drain mode control
    0=NORMAL (Normal. P0.18 pin is in the normal (not open drain) mode.); 1=OPEN_DRAIN (Open-drain. P0.18 pin is in the open drain mode.)
  [17] P0_17OD — Port 0 pin 17 open drain mode control
    0=NORMAL (Normal. P0.17 pin is in the normal (not open drain) mode.); 1=OPEN_DRAIN (Open-drain. P0.17 pin is in the open drain mode.)
  [16] P0_16OD — Port 0 pin 16 open drain mode control
    0=NORMAL (Normal. P0.16 pin is in the normal (not open drain) mode.); 1=OPEN_DRAIN (Open-drain. P0.16 pin is in the open drain mode.)
  [15] P0_15OD — Port 0 pin 15 open drain mode control
    0=NORMAL (Normal. P0.15 pin is in the normal (not open drain) mode.); 1=OPEN_DRAIN (Open-drain. P0.15 pin is in the open drain mode.)
  [11] P0_11OD — Port 0 pin 11 open drain mode control. Pins may potentially be used for I2C-buses using standard port pins. If so, they should be configured for open drain mode via the related bits in PINMODE_OD0.
    0=NORMAL (Normal. P0.11 pin is in the normal (not open drain) mode.); 1=OPEN_DRAIN (Open-drain. P0.11 pin is in the open drain mode.)
  [10] P0_10OD — Port 0 pin 10 open drain mode control. Pins may potentially be used for I2C-buses using standard port pins. If so, they should be configured for open drain mode via the related bits in PINMODE_OD0.
    0=NORMAL (Normal. P0.10 pin is in the normal (not open drain) mode.); 1=OPEN_DRAIN (Open-drain. P0.10 pin is in the open drain mode.)
  [9] P0_09OD — Port 0 pin 9 open drain mode control
    0=NORMAL (Normal. P0.9 pin is in the normal (not open drain) mode.); 1=OPEN_DRAIN (Open-drain. P0.9 pin is in the open drain mode.)
  [8] P0_08OD — Port 0 pin 8 open drain mode control
    0=NORMAL (Normal. P0.8 pin is in the normal (not open drain) mode.); 1=OPEN_DRAIN (Open-drain. P0.8 pin is in the open drain mode.)
  [7] P0_07OD — Port 0 pin 7 open drain mode control
    0=NORMAL (Normal. P0.7 pin is in the normal (not open drain) mode.); 1=OPEN_DRAIN (Open-drain. P0.7 pin is in the open drain mode.)
  [6] P0_06OD — Port 0 pin 6 open drain mode control
    0=NORMAL (Normal. P0.6 pin is in the normal (not open drain) mode.); 1=OPEN_DRAIN (Open-drain. P0.6 pin is in the open drain mode.)
  [5] P0_05OD — Port 0 pin 5 open drain mode control
    0=NORMAL (Normal. P0.5 pin is in the normal (not open drain) mode.); 1=OPEN_DRAIN (Open-drain. P0.5 pin is in the open drain mode.)
  [4] P0_04OD — Port 0 pin 4 open drain mode control
    0=NORMAL (Normal. P0.4 pin is in the normal (not open drain) mode.); 1=OPEN_DRAIN (Open-drain. P0.4 pin is in the open drain mode.)
  [3] P0_03OD — Port 0 pin 3 open drain mode control
    0=NORMAL (Normal. P0.3 pin is in the normal (not open drain) mode.); 1=OPEN_DRAIN (Open-drain. P0.3 pin is in the open drain mode.)
  [2] P0_02OD — Port 0 pin 2 open drain mode control
    0=NORMAL (Normal. P0.2 pin is in the normal (not open drain) mode.); 1=OPEN_DRAIN (Open-drain. P0.2 pin is in the open drain mode.)
  [1] P0_01OD — Port 0 pin 1 open drain mode control. Pins may potentially be used for I2C-buses using standard port pins. If so, they should be configured for open drain mode via the related bits in PINMODE_OD0.
    0=NORMAL (Normal. P0.1 pin is in the normal (not open drain) mode.); 1=OPEN_DRAIN (Open-drain. P0.1 pin is in the open drain mode.)
  [0] P0_00OD — Port 0 pin 0 open drain mode control. Pins may potentially be used for I2C-buses using standard port pins. If so, they should be configured for open drain mode via the related bits in PINMODE_OD0.
    0=NORMAL (Normal. P0.0 pin is in the normal (not open drain) mode.); 1=OPEN_DRAIN (Open-drain. P0.0 pin is in the open drain mode.)
0x6C PINMODE_OD1 reset 0x0 — Open drain mode control register 1
  [31] P1_31OD — Port 1 pin 31 open drain mode control.
    0=NORMAL (Normal. P1.31 pin is in the normal (not open drain) mode.); 1=OPEN_DRAIN (Open-drain. P1.31 pin is in the open drain mode.)
  [30] P1_30OD — Port 1 pin 30 open drain mode control, see P1.00OD
    0=NORMAL (Normal. P1.30 pin is in the normal (not open drain) mode.); 1=OPEN_DRAIN (Open-drain. P1.30 pin is in the open drain mode.)
  [29] P1_29OD — Port 1 pin 29 open drain mode control, see P1.00OD
    0=NORMAL (Normal. P1.29 pin is in the normal (not open drain) mode.); 1=OPEN_DRAIN (Open-drain. P1.29 pin is in the open drain mode.)
  [28] P1_28OD — Port 1 pin 28 open drain mode control, see P1.00OD
    0=NORMAL (Normal. P1.28 pin is in the normal (not open drain) mode.); 1=OPEN_DRAIN (Open-drain. P1.28 pin is in the open drain mode.)
  [27] P1_27OD — Port 1 pin 27 open drain mode control, see P1.00OD
    0=NORMAL (Normal. P1.27 pin is in the normal (not open drain) mode.); 1=OPEN_DRAIN (Open-drain. P1.27 pin is in the open drain mode.)
  [26] P1_26OD — Port 1 pin 26 open drain mode control, see P1.00OD
    0=NORMAL (Normal. P1.26 pin is in the normal (not open drain) mode.); 1=OPEN_DRAIN (Open-drain. P1.26 pin is in the open drain mode.)
  [25] P1_25OD — Port 1 pin 25 open drain mode control, see P1.00OD
    0=NORMAL (Normal. P1.25 pin is in the normal (not open drain) mode.); 1=OPEN_DRAIN (Open-drain. P1.25 pin is in the open drain mode.)
  [24] P1_24OD — Port 1 pin 24open drain mode control, see P1.00OD
    0=NORMAL (Normal. P1.24 pin is in the normal (not open drain) mode.); 1=OPEN_DRAIN (Open-drain. P1.24 pin is in the open drain mode.)
  [23] P1_23OD — Port 1 pin 23 open drain mode control, see P1.00OD
    0=NORMAL (Normal. P1.23 pin is in the normal (not open drain) mode.); 1=OPEN_DRAIN (Open-drain. P1.23 pin is in the open drain mode.)
  [22] P1_22OD — Port 1 pin 22 open drain mode control, see P1.00OD
    0=NORMAL (Normal. P1.22 pin is in the normal (not open drain) mode.); 1=OPEN_DRAIN (Open-drain. P1.22 pin is in the open drain mode.)
  [21] P1_21OD — Port 1 pin 21 open drain mode control, see P1.00OD
    0=NORMAL (Normal. P1.21 pin is in the normal (not open drain) mode.); 1=OPEN_DRAIN (Open-drain. P1.21 pin is in the open drain mode.)
  [20] P1_20OD — Port 1 pin 20open drain mode control, see P1.00OD
    0=NORMAL (Normal. P1.20 pin is in the normal (not open drain) mode.); 1=OPEN_DRAIN (Open-drain. P1.20 pin is in the open drain mode.)
  [19] P1_19OD — Port 1 pin 19 open drain mode control, see P1.00OD
    0=NORMAL (Normal. P1.19 pin is in the normal (not open drain) mode.); 1=OPEN_DRAIN (Open-drain. P1.19 pin is in the open drain mode.)
  [18] P1_18OD — Port 1 pin 18 open drain mode control, see P1.00OD
    0=NORMAL (Normal. P1.18 pin is in the normal (not open drain) mode.); 1=OPEN_DRAIN (Open-drain. P1.18 pin is in the open drain mode.)
  [17] P1_17OD — Port 1 pin 17 open drain mode control, see P1.00OD
    0=NORMAL (Normal. P1.17 pin is in the normal (not open drain) mode.); 1=OPEN_DRAIN (Open-drain. P1.17 pin is in the open drain mode.)
  [16] P1_16OD — Port 1 pin 16 open drain mode control, see P1.00OD
    0=NORMAL (Normal. P1.16 pin is in the normal (not open drain) mode.); 1=OPEN_DRAIN (Open-drain. P1.16 pin is in the open drain mode.)
  [15] P1_15OD — Port 1 pin 15 open drain mode control, see P1.00OD
    0=NORMAL (Normal. P1.15 pin is in the normal (not open drain) mode.); 1=OPEN_DRAIN (Open-drain. P1.15 pin is in the open drain mode.)
  [14] P1_14OD — Port 1 pin 14 open drain mode control, see P1.00OD
    0=NORMAL (Normal. P1.14 pin is in the normal (not open drain) mode.); 1=OPEN_DRAIN (Open-drain. P1.14 pin is in the open drain mode.)
  [10] P1_10OD — Port 1 pin 10 open drain mode control, see P1.00OD
    0=NORMAL (Normal. P1.10 pin is in the normal (not open drain) mode.); 1=OPEN_DRAIN (Open-drain. P1.10 pin is in the open drain mode.)
  [9] P1_09OD — Port 1 pin 9 open drain mode control, see P1.00OD
    0=NORMAL (Normal. P1.9 pin is in the normal (not open drain) mode.); 1=OPEN_DRAIN (Open-drain. P1.9 pin is in the open drain mode.)
  [8] P1_08OD — Port 1 pin 8 open drain mode control, see P1.00OD
    0=NORMAL (Normal. P1.8 pin is in the normal (not open drain) mode.); 1=OPEN_DRAIN (Open-drain. P1.8 pin is in the open drain mode.)
  [4] P1_04OD — Port 1 pin 4 open drain mode control, see P1.00OD
    0=NORMAL (Normal. P1.4 pin is in the normal (not open drain) mode.); 1=OPEN_DRAIN (Open-drain. P1.4 pin is in the open drain mode.)
  [1] P1_01OD — Port 1 pin 1 open drain mode control, see P1.00OD
    0=NORMAL (Normal. P1.1 pin is in the normal (not open drain) mode.); 1=OPEN_DRAIN (Open-drain. P1.1 pin is in the open drain mode.)
  [0] P1_00OD — Port 1 pin 0 open drain mode control.
    0=NORMAL (Normal. P1.0 pin is in the normal (not open drain) mode.); 1=OPEN_DRAIN (Open-drain. P1.0 pin is in the open drain mode.)
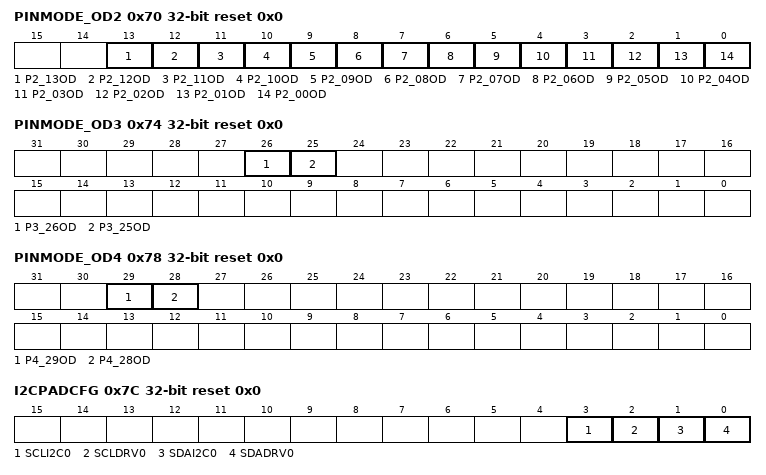
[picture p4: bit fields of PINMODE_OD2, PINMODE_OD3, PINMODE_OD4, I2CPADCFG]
0x70 PINMODE_OD2 reset 0x0 — Open drain mode control register 2
  [13] P2_13OD — Port 2 pin 13 open drain mode control, see P2.00OD
    0=NORMAL (Normal. P2.13 pin is in the normal (not open drain) mode.); 1=OPEN_DRAIN (Open-drain. P2.13 pin is in the open drain mode.)
  [12] P2_12OD — Port 2 pin 12 open drain mode control, see P2.00OD
    0=NORMAL (Normal. P2.12 pin is in the normal (not open drain) mode.); 1=OPEN_DRAIN (Open-drain. P2.12 pin is in the open drain mode.)
  [11] P2_11OD — Port 2 pin 11 open drain mode control, see P2.00OD
    0=NORMAL (Normal. P2.11 pin is in the normal (not open drain) mode.); 1=OPEN_DRAIN (Open-drain. P2.11 pin is in the open drain mode.)
  [10] P2_10OD — Port 2 pin 10 open drain mode control, see P2.00OD
    0=NORMAL (Normal. P2.10 pin is in the normal (not open drain) mode.); 1=OPEN_DRAIN (Open-drain. P2.10 pin is in the open drain mode.)
  [9] P2_09OD — Port 2 pin 9 open drain mode control, see P2.00OD
    0=NORMAL (Normal. P2.9 pin is in the normal (not open drain) mode.); 1=OPEN_DRAIN (Open-drain. P2.9 pin is in the open drain mode.)
  [8] P2_08OD — Port 2 pin 8 open drain mode control, see P2.00OD
    0=NORMAL (Normal. P2.8 pin is in the normal (not open drain) mode.); 1=OPEN_DRAIN (Open-drain. P2.8 pin is in the open drain mode.)
  [7] P2_07OD — Port 2 pin 7 open drain mode control, see P2.00OD
    0=NORMAL (Normal. P2.7 pin is in the normal (not open drain) mode.); 1=OPEN_DRAIN (Open-drain. P2.7 pin is in the open drain mode.)
  [6] P2_06OD — Port 2 pin 6 open drain mode control, see P2.00OD
    0=NORMAL (Normal. P2.6 pin is in the normal (not open drain) mode.); 1=OPEN_DRAIN (Open-drain. P2.6 pin is in the open drain mode.)
  [5] P2_05OD — Port 2 pin 5 open drain mode control, see P2.00OD
    0=NORMAL (Normal. P2.5 pin is in the normal (not open drain) mode.); 1=OPEN_DRAIN (Open-drain. P2.5 pin is in the open drain mode.)
  [4] P2_04OD — Port 2 pin 4 open drain mode control, see P2.00OD
    0=NORMAL (Normal. P2.4 pin is in the normal (not open drain) mode.); 1=OPEN_DRAIN (Open-drain. P2.4 pin is in the open drain mode.)
  [3] P2_03OD — Port 2 pin 3 open drain mode control, see P2.00OD
    0=NORMAL (Normal. P2.3 pin is in the normal (not open drain) mode.); 1=OPEN_DRAIN (Open-drain. P2.3 pin is in the open drain mode.)
  [2] P2_02OD — Port 2 pin 2 open drain mode control, see P2.00OD
    0=NORMAL (Normal. P2.2 pin is in the normal (not open drain) mode.); 1=OPEN_DRAIN (Open-drain. P2.2 pin is in the open drain mode.)
  [1] P2_01OD — Port 2 pin 1 open drain mode control, see P2.00OD
    0=NORMAL (Normal. P2.1 pin is in the normal (not open drain) mode.); 1=OPEN_DRAIN (Open-drain. P2.1p in is in the open drain mode.)
  [0] P2_00OD — Port 2 pin 0 open drain mode control.
    0=NORMAL (Normal. P2.0 pin is in the normal (not open drain) mode.); 1=OPEN_DRAIN (Open-drain. P2.0 pin is in the open drain mode.)
0x74 PINMODE_OD3 reset 0x0 — Open drain mode control register 3
  [26] P3_26OD — Port 3 pin 26 open drain mode control, see P3.25OD
  [25] P3_25OD — Port 3 pin 25 open drain mode control.
    0=NORMAL (Normal. P3.25 pin is in the normal (not open drain) mode.); 1=OPEN_DRAIN (Open-drain. P3.25 pin is in the open drain mode.)
0x78 PINMODE_OD4 reset 0x0 — Open drain mode control register 4
  [29] P4_29OD — Port 4 pin 29 open drain mode control, see P4.28OD
  [28] P4_28OD — Port 4 pin 28 open drain mode control.
    0=NORMAL (Normal. P4.28 pin is in the normal (not open drain) mode.); 1=OPEN_DRAIN (Open-drain. P4.28 pin is in the open drain mode.)
0x7C I2CPADCFG reset 0x0 — I2C Pin Configuration register
  [3] SCLI2C0 — I 2C filter mode control for the SCL0 pin, P0.28.
    0=ENABLED (Enabled. The SCL0 pin has I2C glitch filtering and slew rate control enabled.); 1=DISABLED (Disabled. The SCL0 pin has I2C glitch filtering and slew rate control disabled.)
  [2] SCLDRV0 — Drive mode control for the SCL0 pin, P0.28.
    0=STANDARD (Standard. The SCL0 pin is in the standard drive mode.); 1=FAST_MODE_PLUS (Fast-mode plus. The SCL0 pin is in Fast Mode Plus drive mode.)
  [1] SDAI2C0 — I 2C filter mode control for the SDA0 pin, P0.27.
    0=ENABLED (Enabled. The SDA0 pin has I2C glitch filtering and slew rate control enabled.); 1=DISABLED (Disabled. The SDA0 pin has I2C glitch filtering and slew rate control disabled.)
  [0] SDADRV0 — Drive mode control for the SDA0 pin, P0.27.
    0=STANDARD (Standard. The SDA0 pin is in the standard drive mode.); 1=FAST_MODE_PLUS (Fast-mode plus. The SDA0 pin is in Fast Mode Plus drive mode.)
